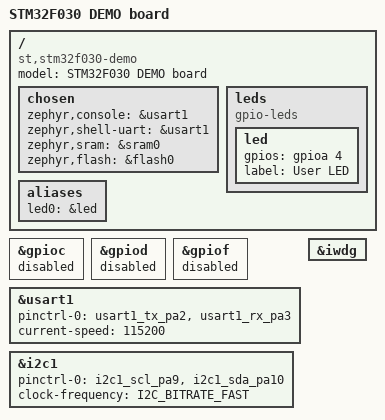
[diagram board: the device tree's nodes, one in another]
/*
 * Copyright (c) 2019 Antony Pavlov <antonynpavlov@gmail.com>
 *
 * SPDX-License-Identifier: Apache-2.0
 */

/dts-v1/;
#include <st/f0/stm32f030X4.dtsi>
#include <st/f0/stm32f030f4px-pinctrl.dtsi>

/ {
	model = "STM32F030 DEMO board";
	compatible = "st,stm32f030-demo";

	chosen {
		zephyr,console = &usart1;
		zephyr,shell-uart = &usart1;
		zephyr,sram = &sram0;
		zephyr,flash = &flash0;
	};

	leds {
		compatible = "gpio-leds";
		led: led {
			gpios = <&gpioa 4 GPIO_ACTIVE_HIGH>;
			label = "User LED";
		};
	};

	aliases {
		led0 = &led;
	};
};

/* Due to limited available memory, don't enable gpioc,d,e,f */
&gpioc {status = "disabled";};
&gpiod {status = "disabled";};
&gpiof {status = "disabled";};

&usart1 {
	pinctrl-0 = <&usart1_tx_pa2 &usart1_rx_pa3>;
	current-speed = <115200>;
	status = "okay";
};
&i2c1 {
	pinctrl-0 = < &i2c1_scl_pa9 &i2c1_sda_pa10 >;
	status = "okay";
	clock-frequency = <I2C_BITRATE_FAST>;
};


&iwdg {
	status = "okay";
};
